# STM32F469AEH6 register map
File version: 1.0
Registers are 32-bit, access not given, reset 0x0 unless marked. A register's access mark holds for its fields unless they carry their own. Offsets are from the block's base; [hi:lo] are bit positions; {n}, {i} and the like mark numbered series.

## DSIH
Base 0x40016C00
0x00 VR
  [31:0] VERSION
0x04 CR
  [0] EN
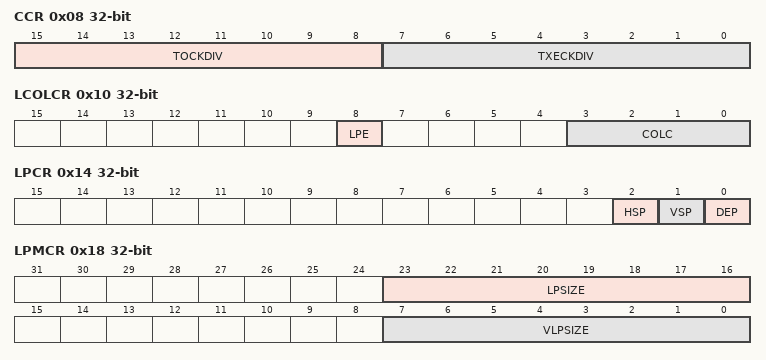
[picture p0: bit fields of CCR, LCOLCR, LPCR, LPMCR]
0x08 CCR
  [15:8] TOCKDIV, [7:0] TXECKDIV
0x0C LVCIDR
  [1:0] VCID
0x10 LCOLCR
  [8] LPE, [3:0] COLC
0x14 LPCR
  [2] HSP, [1] VSP, [0] DEP
0x18 LPMCR
  [23:16] LPSIZE, [7:0] VLPSIZE
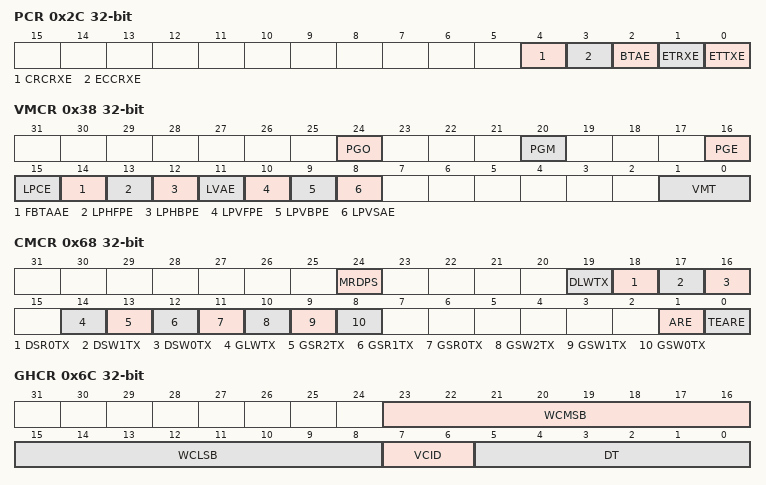
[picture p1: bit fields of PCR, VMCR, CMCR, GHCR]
0x2C PCR
  [4] CRCRXE, [3] ECCRXE, [2] BTAE, [1] ETRXE, [0] ETTXE
0x30 GVCIDR
  [1:0] VCID
0x34 MCR
  [0] CMDM
0x38 VMCR
  [24] PGO, [20] PGM, [16] PGE, [15] LPCE, [14] FBTAAE, [13] LPHFPE, [12] LPHBPE, [11] LVAE, [10] LPVFPE, [9] LPVBPE, [8] LPVSAE, [1:0] VMT
0x3C VPCR
  [14:0] VPSIZE
0x40 VCCR
  [13:0] NUMC
0x44 VNPCR
  [13:0] NPSIZE
0x48 VHSACR
  [12:0] HSA
0x4C VHBPCR
  [12:0] HBP
0x50 VLCR
  [14:0] HLINE
0x54 VVSACR
  [9:0] VSA
0x58 VVBPCR
  [9:0] VBP
0x5C VVFPCR
  [9:0] VFP
0x60 VVACR
  [13:0] VA
0x64 LCCR
  [15:0] CMDSIZE
0x68 CMCR
  [24] MRDPS, [19] DLWTX, [18] DSR0TX, [17] DSW1TX, [16] DSW0TX, [14] GLWTX, [13] GSR2TX, [12] GSR1TX, [11] GSR0TX, [10] GSW2TX, [9] GSW1TX, [8] GSW0TX, [1] ARE, [0] TEARE
0x6C GHCR
  [23:16] WCMSB, [15:8] WCLSB, [7:6] VCID, [5:0] DT
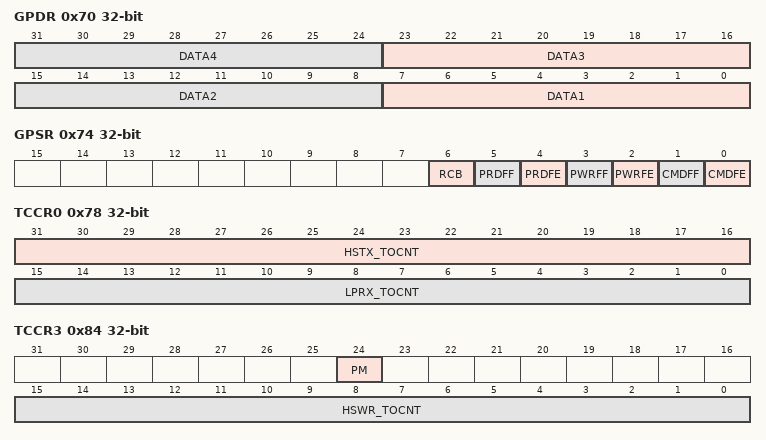
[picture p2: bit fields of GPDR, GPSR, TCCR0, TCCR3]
0x70 GPDR
  [8n-1:8n-8] DATA{n} (n=1..4)
0x74 GPSR
  [6] RCB, [5] PRDFF, [4] PRDFE, [3] PWRFF, [2] PWRFE, [1] CMDFF, [0] CMDFE
0x78 TCCR0
  [31:16] HSTX_TOCNT, [15:0] LPRX_TOCNT
0x7C TCCR1
  [15:0] HSRD_TOCNT
0x80 TCCR2
  [15:0] LPRD_TOCNT
0x84 TCCR3
  [24] PM, [15:0] HSWR_TOCNT
0x88 TCCR4
  [15:0] LSWR_TOCNT
0x8C TCCR5
  [15:0] BTA_TOCNT
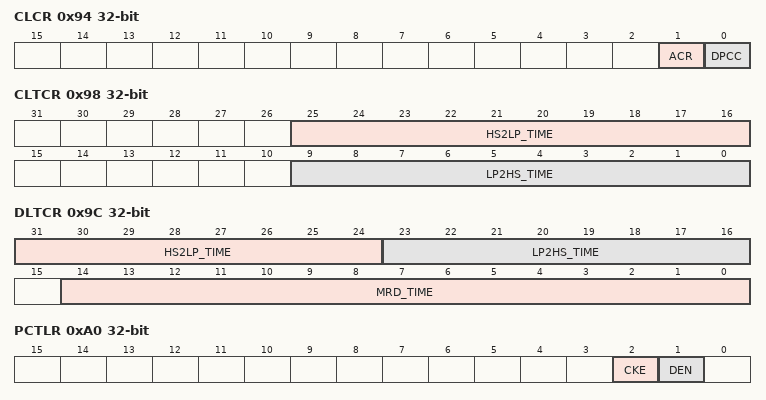
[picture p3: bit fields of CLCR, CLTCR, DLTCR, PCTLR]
0x94 CLCR
  [1] ACR, [0] DPCC
0x98 CLTCR
  [25:16] HS2LP_TIME, [9:0] LP2HS_TIME
0x9C DLTCR
  [31:24] HS2LP_TIME, [23:16] LP2HS_TIME, [14:0] MRD_TIME
0xA0 PCTLR
  [2] CKE, [1] DEN
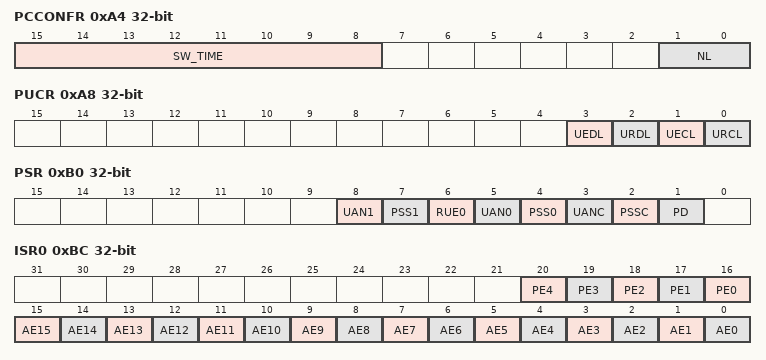
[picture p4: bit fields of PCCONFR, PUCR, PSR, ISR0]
0xA4 PCCONFR
  [15:8] SW_TIME, [1:0] NL
0xA8 PUCR
  [3] UEDL, [2] URDL, [1] UECL, [0] URCL
0xAC PTTCR
  [3:0] TX_TRIG
0xB0 PSR
  [8] UAN1, [7] PSS1, [6] RUE0, [5] UAN0, [4] PSS0, [3] UANC, [2] PSSC, [1] PD
0xBC ISR0
  [n+16] PE{n} (n=0..4), [n] AE{n} (n=0..15)
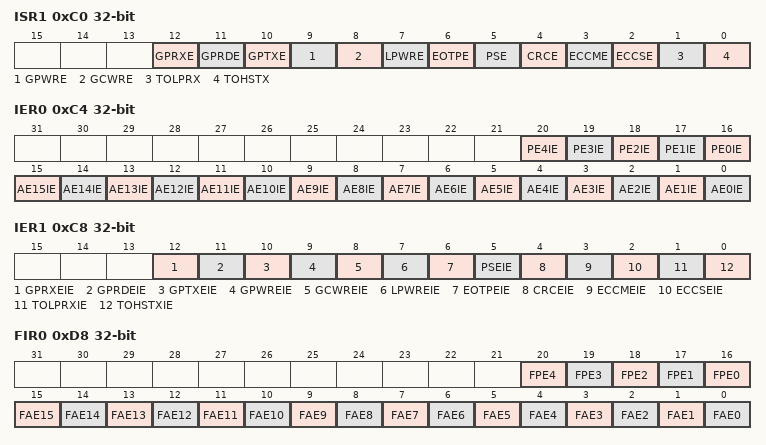
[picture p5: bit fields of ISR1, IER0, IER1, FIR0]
0xC0 ISR1
  [12] GPRXE, [11] GPRDE, [10] GPTXE, [9] GPWRE, [8] GCWRE, [7] LPWRE, [6] EOTPE, [5] PSE, [4] CRCE, [3] ECCME, [2] ECCSE, [1] TOLPRX, [0] TOHSTX
0xC4 IER0
  [n+16] PE{n}IE (n=0..4), [n] AE{n}IE (n=0..15)
0xC8 IER1
  [12] GPRXEIE, [11] GPRDEIE, [10] GPTXEIE, [9] GPWREIE, [8] GCWREIE, [7] LPWREIE, [6] EOTPEIE, [5] PSEIE, [4] CRCEIE, [3] ECCMEIE, [2] ECCSEIE, [1] TOLPRXIE, [0] TOHSTXIE
0xD8 FIR0
  [n+16] FPE{n} (n=0..4), [n] FAE{n} (n=0..15)
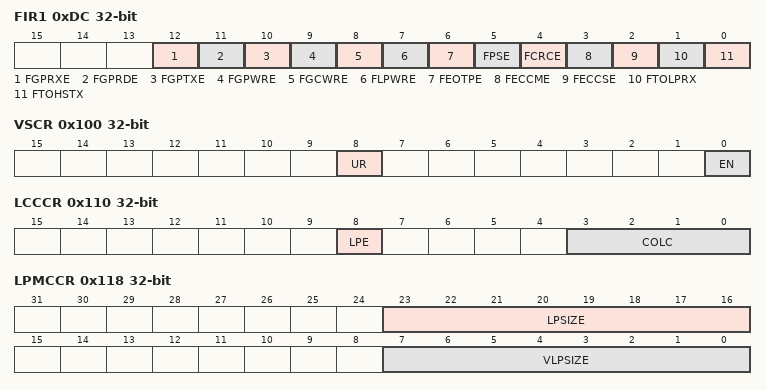
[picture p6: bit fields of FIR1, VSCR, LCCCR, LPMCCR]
0xDC FIR1
  [12] FGPRXE, [11] FGPRDE, [10] FGPTXE, [9] FGPWRE, [8] FGCWRE, [7] FLPWRE, [6] FEOTPE, [5] FPSE, [4] FCRCE, [3] FECCME, [2] FECCSE, [1] FTOLPRX, [0] FTOHSTX
0x100 VSCR
  [8] UR, [0] EN
0x10C LCVCIDR
  [1:0] VCID
0x110 LCCCR
  [8] LPE, [3:0] COLC
0x118 LPMCCR
  [23:16] LPSIZE, [7:0] VLPSIZE
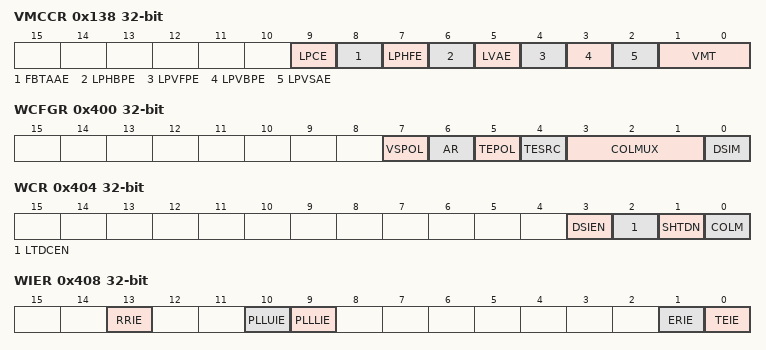
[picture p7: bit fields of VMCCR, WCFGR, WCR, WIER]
0x138 VMCCR
  [9] LPCE, [8] FBTAAE, [7] LPHFE, [6] LPHBPE, [5] LVAE, [4] LPVFPE, [3] LPVBPE, [2] LPVSAE, [1:0] VMT
0x13C VPCCR
  [14:0] VPSIZE
0x140 VCCCR
  [13:0] NUMC
0x144 VNPCCR
  [13:0] NPSIZE
0x148 VHSACCR
  [12:0] HSA
0x14C VHBPCCR
  [12:0] HBP
0x150 VLCCR
  [14:0] HLINE
0x154 VVSACCR
  [9:0] VSA
0x158 VVBPCCR
  [9:0] VBP
0x15C VVFPCCR
  [9:0] VFP
0x160 VVACCR
  [13:0] VA
0x400 WCFGR
  [7] VSPOL, [6] AR, [5] TEPOL, [4] TESRC, [3:1] COLMUX, [0] DSIM
0x404 WCR
  [3] DSIEN, [2] LTDCEN, [1] SHTDN, [0] COLM
0x408 WIER
  [13] RRIE, [10] PLLUIE, [9] PLLLIE, [1] ERIE, [0] TEIE
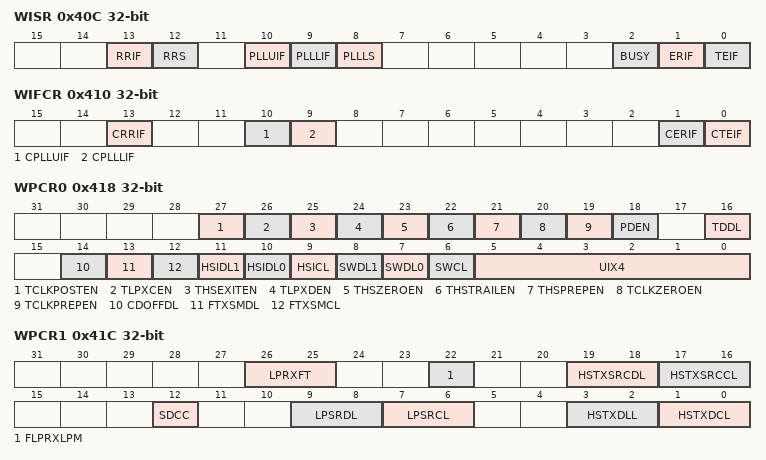
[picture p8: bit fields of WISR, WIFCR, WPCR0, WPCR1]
0x40C WISR
  [13] RRIF, [12] RRS, [10] PLLUIF, [9] PLLLIF, [8] PLLLS, [2] BUSY, [1] ERIF, [0] TEIF
0x410 WIFCR
  [13] CRRIF, [10] CPLLUIF, [9] CPLLLIF, [1] CERIF, [0] CTEIF
0x418 WPCR0
  [27] TCLKPOSTEN, [26] TLPXCEN, [25] THSEXITEN, [24] TLPXDEN, [23] THSZEROEN, [22] THSTRAILEN, [21] THSPREPEN, [20] TCLKZEROEN, [19] TCLKPREPEN, [18] PDEN, [16] TDDL, [14] CDOFFDL, [13] FTXSMDL, [12] FTXSMCL, [11] HSIDL1, [10] HSIDL0, [9] HSICL, [8] SWDL1, [7] SWDL0, [6] SWCL, [5:0] UIX4
0x41C WPCR1
  [26:25] LPRXFT, [22] FLPRXLPM, [19:18] HSTXSRCDL, [17:16] HSTXSRCCL, [12] SDCC, [9:8] LPSRDL, [7:6] LPSRCL, [3:2] HSTXDLL, [1:0] HSTXDCL
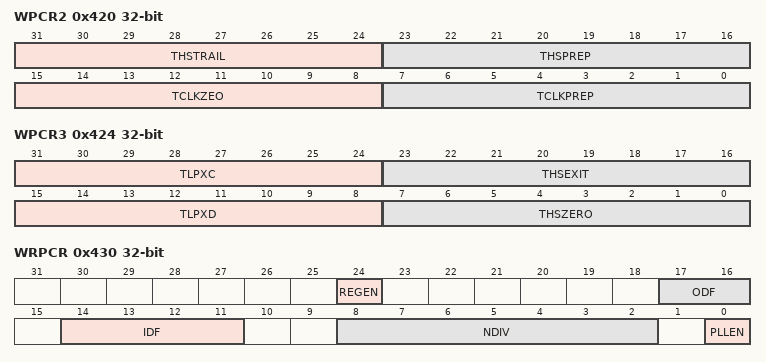
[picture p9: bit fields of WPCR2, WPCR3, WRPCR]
0x420 WPCR2
  [31:24] THSTRAIL, [23:16] THSPREP, [15:8] TCLKZEO, [7:0] TCLKPREP
0x424 WPCR3
  [31:24] TLPXC, [23:16] THSEXIT, [15:8] TLPXD, [7:0] THSZERO
0x428 WPCR4
  [7:0] THSZERO
0x430 WRPCR
  [24] REGEN, [17:16] ODF, [14:11] IDF, [8:2] NDIV, [0] PLLEN
